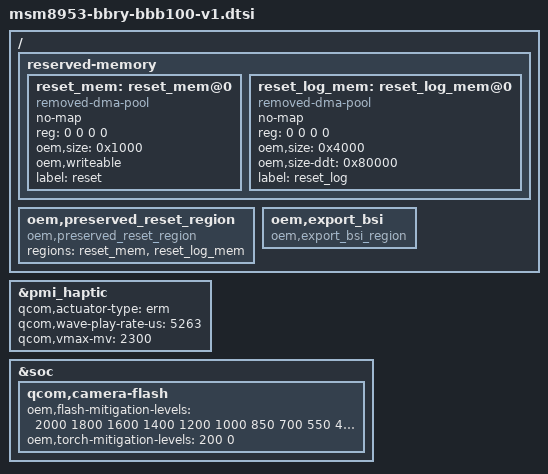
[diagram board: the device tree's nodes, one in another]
/* Copyright (C) 2016 BlackBerry Limited. All rights reserved.
 * Copyright (c) 2014, The Linux Foundation. All rights reserved.
 *
 * This program is free software; you can redistribute it and/or modify
 * it under the terms of the GNU General Public License version 2 and
 * only version 2 as published by the Free Software Foundation.
 *
 * This program is distributed in the hope that it will be useful,
 * but WITHOUT ANY WARRANTY; without even the implied warranty of
 * MERCHANTABILITY or FITNESS FOR A PARTICULAR PURPOSE.  See the
 * GNU General Public License for more details.
 */

/ {
	reserved-memory {
		#address-cells = <0x2>;
		#size-cells = <0x2>;
		reset_mem: reset_mem@0 {
			compatible = "removed-dma-pool";
			no-map;
			/*
			 * Bootloader take the address from the oem,size props
			 * and insert it here along with the address
			 */
			reg = <0 0 0 0>;
			oem,size = <0x1000>;
			oem,writeable;
			label = "reset";
		};

		reset_log_mem: reset_log_mem@0 {
			compatible = "removed-dma-pool";
			no-map;
			/*
			 * Bootloader take the address from the oem,size props
			 * and insert it here along with the address
			 */
			reg = <0 0 0 0>;
			oem,size = <0x4000>;
			/* If ddt is enabled, we reserve more memory */
			oem,size-ddt = <0x80000>;
			label = "reset_log";
		};
	};

	oem,preserved_reset_region {
		compatible = "oem,preserved_reset_region";
		regions = <&reset_mem &reset_log_mem> ;
	};

	oem,export_bsi {
		compatible = "oem,export_bsi_region", "oem,export_bsi";
	};

};

/* MODIFIED-BEGIN by hongwei.tian, 2016-07-29,BUG-2635028*/
&pmi_haptic{
	qcom,actuator-type = "erm";
	qcom,wave-play-rate-us = <5263>;
	qcom,vmax-mv = <2300>; // MODIFIED by TCNNB.xqj, 2017-01-15,BUG-3655608
};
/* MODIFIED-END by hongwei.tian,BUG-2635028*/

/*
 * Flash Mitigation Levels
 */
&soc {
	qcom,camera-flash {
		oem,flash-mitigation-levels = <2000 1800 1600 1400 1200 1000
						850 700 550 400 200 100 0>;
		oem,torch-mitigation-levels = <200 0>;
	};
};
